# DSS_DSS_VP1_3020A000h register map
Vendor: Texas Instruments
Peripheral module from a debugger description file (folder am62L).
Registers are 32-bit, read-write, reset 0x0 unless marked. A register's access mark holds for its fields unless they carry their own. Offsets are as the file gives them; lines under a group give offsets from that group; [hi:lo] are bit positions; {n}, {i} and the like mark numbered series; 'fields as' and 'values as' point back to an identical list; <NAME> marks a mode.

## DSS_VP1
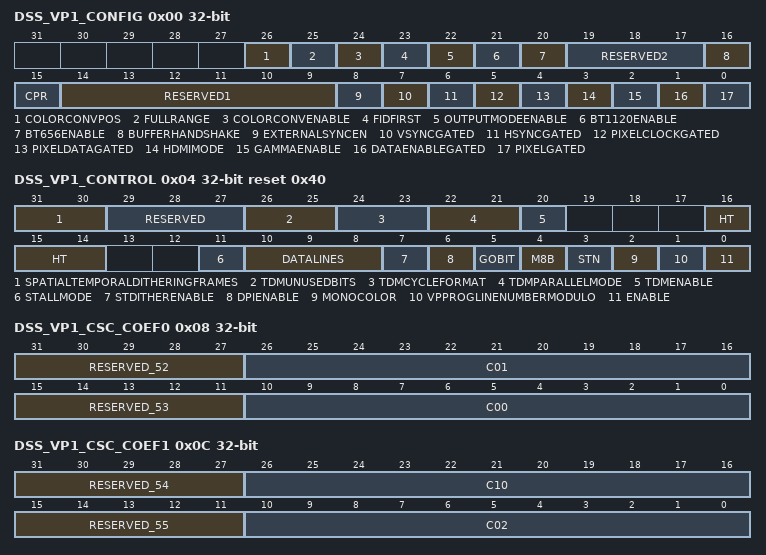
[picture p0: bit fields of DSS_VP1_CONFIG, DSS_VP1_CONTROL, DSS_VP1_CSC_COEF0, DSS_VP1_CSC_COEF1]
0x00 DSS_VP1_CONFIG access per field — The control register configures the Display Controller module for the VP output. Shadow register.
  [26] COLORCONVPOS rw — Determines the position of the COLORCONV module 0 CSC block is after GAMMA correction1 CSC block is before GAMMA correction
  [25] FULLRANGE rw — Color Space Conversion full range setting 0 Limited range selected.1 Full range selected.
  [24] COLORCONVENABLE rw — Enable the color space conversion. The coefficients and offsets used are all programmable and controlled by CPR_COEFF_* and CPR_OFFSET_* registers 0 Disable Color Space Conversion RGB to YUV1 Enable Color Space Conversion RGB to YUV
  [23] FIDFIRST rw — Selects the first field to output in case of interlace mode. In case of progressive mode, the value is not used 0 First field is even.1 Odd field is first.
  [22] OUTPUTMODEENABLE rw — Selects between progressive and interlace mode for the VP output 0 Progressive mode selected.1 Interlace mode selected.
  [21] BT1120ENABLE rw — Selects BT-1120 format on the VP output. It is not possible to enable BT656 and BT1120 at the same time one the same LCD output 0 BT-1120 is disabled.1 BT-1120 is enabled.
  [20] BT656ENABLE rw — Selects BT-656 format on the VP output. It is not possible to enable BT656 and BT1120 at the same time one the same LCD output 0 BT-656 is disabled.1 BT-656 is enabled.
  [19:17] RESERVED2 ro — Write 0's for future compatibility Reads return 0
  [16] BUFFERHANDSHAKE rw — Deprecated. Always write 0
  [15] CPR rw — Deprecated. Always write 0
  [14:9] RESERVED1 ro — Write 0's for future compatibility Reads return 0
  [8] EXTERNALSYNCEN rw — Deprecated. Always write 0
  [7] VSYNCGATED rw — VSYNC Gated Enabled [VP output]. Shadow bit-field 0 VSYNC Gated Disabled1 VSYNC Gated Enabled
  [6] HSYNCGATED rw — HSYNC Gated Enabled [VP output]. Shadow bit-field 0 HSYNC Gated Disabled1 HSYNC Gated Enabled
  [5] PIXELCLOCKGATED rw — Pixel Clock Gated Enabled [VP output]. Shadow bit-field 0 Pixel Clock Gated Disabled1 Pixel Clock Gated Enabled
  [4] PIXELDATAGATED rw — Pixel Data Gated Enabled [VP output]. Shadow bit-field 0 Pixel Data Gated Disabled1 Pixel Data Gated Enabled
  [3] HDMIMODE rw — Deprecated. Always write 0
  [2] GAMMAENABLE rw — Enable the gamma Shadow bit-field 0 Gamma disabled1 Gamma enabled
  [1] DATAENABLEGATED rw — DE Gated Enable Shadow bit-field 0 DE signal is not gated1 DE signal is gated.
  [0] PIXELGATED rw — Pixel Gated Enable. Shadow bit-field 0 Pixel clock always toggles - only in TFT mode1 Pixel clock only toggles when there is valid data to display -only in TFT mode
0x04 DSS_VP1_CONTROL access per field reset 0x40 — The control register configures the Display Controller module for the VP output
  [31:30] SPATIALTEMPORALDITHERINGFRAMES rw — Spatial/Temporal dithering number of frames for the VP output Shadow bit-field 0 Spatial only1 Spatial and temporal over 2 frames2 Spatial and temporal over 4 frames3 Reserved
  [29:27] RESERVED ro — Write 0's for future compatibility Reads return 0
  [26:25] TDMUNUSEDBITS rw — State of unused bits [TDM mode only] for the VP output Shadow bit-field 0 low level1 high level2 unchanged from previous state3 reserved
  [24:23] TDMCYCLEFORMAT rw — Cycle format [TDM mode only] for the VP output Shadow bit-field 0 1 cycle for 1 pixel1 2 cycles for 1 pixel2 3 cycles for 1 pixel3 3 cycles for 2 pixels
  [22:21] TDMPARALLELMODE rw — Output Interface width [TDM mode only] for the VP output Shadow bit-field 0 8-bit parallel output interface selected1 9-bit parallel output interface selected2 12-bit parallel output interface selected3 16-bit parallel output interface selected
  [20] TDMENABLE rw — Enable the multiple cycle format for the VP output Shadow bit-field 0 TDM disabled1 TDM enabled
  [16:14] HT rw — Hold Time for output. Shadow bit-field. Encoded value [from 1 to 8] to specify the number of external digital clock periods to hold the data [programmed value = value minus one]
  [11] STALLMODE rw — Deprecated. Always write 0
  [10:8] DATALINES rw — Width of the data bus on VP output Shadow bit-field 0 12-bit output aligned on the LSB of the pixel data interface1 16-bit output aligned on the LSB of the pixel data interface2 18-bit output aligned on the LSB of the pixel data interface3 24-bit output aligned on the LSB of the pixel data interface4 30-bit output aligned on the LSB of the pixel data interface5 36-bit output aligned on the LSB of the pixel data interface
  [7] STDITHERENABLE rw — Spatial Temporal dithering enable for the VP output Shadow bit-field 0 Spatial/Temporal dithering logic disabled1 Spatial/Temporal dithering logic enabled
  [6] DPIENABLE rw — Enable the DPI output and mdata[8] is driven by this bitfield, there is no other functionality in DSS_Nano driven by this bit . wr:immediate 0 DPI output disabled1 DPI output enabled
  [5] GOBIT rw — GO Command for the VP output. It is used to synchronize the pipelines associated with the VP output wr:immediate 0 The hardware has finished the synchronization1 Software has requested for synchronization after register updates and the hardware has not finished the synchronization
  [4] M8B rw — Deprecated. Always write 0
  [3] STN rw — Deprecated. Always write 0
  [2] MONOCOLOR rw — Deprecated. Always write 0
  [1] VPPROGLINENUMBERMODULO rw — Enable the modulo of the line number interrupt generation 0 Disable modulo1 Enable Modulo
  [0] ENABLE rw — Enable the video port output. wr:immediate 0 LCD output disabled-at the end of the frame when the bit is reset1 LCD output enabled
0x08 DSS_VP1_CSC_COEF0 access per field — The register configures the color space conversion matrix coefficients. Shadow register
  [31:27] RESERVED_52 ro — Write 0's for future compatibility. Reads return 0
  [26:16] C01 rw — C01 Coefficient. Encoded signed value [from -1024 to 1023]
  [15:11] RESERVED_53 ro — Write 0's for future compatibility. Reads return 0
  [10:0] C00 rw — C00 Coefficient. Encoded signed value [from -1024 to 1023]
0x0C DSS_VP1_CSC_COEF1 access per field — The register configures the color space conversion matrix coefficients. Shadow register
  [31:27] RESERVED_54 ro — Write 0's for future compatibility. Reads return 0
  [26:16] C10 rw — C10 Coefficient. Encoded signed value [from -1024 to 1023]
  [15:11] RESERVED_55 ro — Write 0's for future compatibility. Reads return 0
  [10:0] C02 rw — C02 Coefficient. Encoded signed value [from -1024 to 1023]
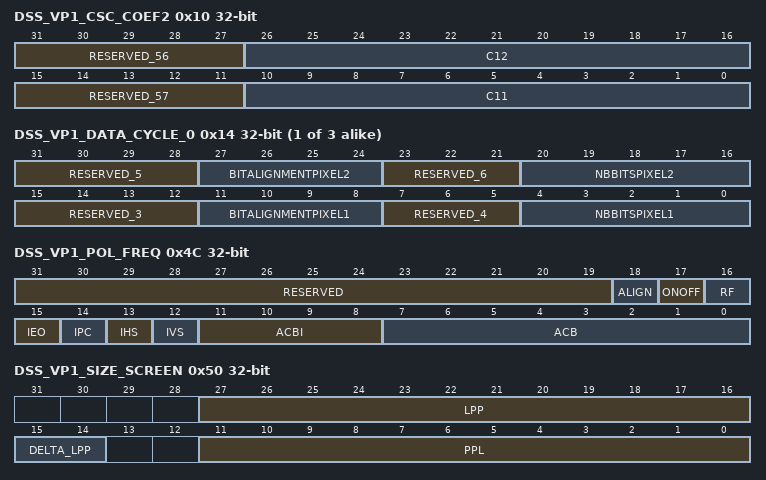
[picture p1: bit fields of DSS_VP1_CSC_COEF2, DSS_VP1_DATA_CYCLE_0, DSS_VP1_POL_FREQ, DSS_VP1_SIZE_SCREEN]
0x10 DSS_VP1_CSC_COEF2 access per field — The register configures the color space conversion matrix coefficients. Shadow register
  [31:27] RESERVED_56 ro — Write 0's for future compatibility Reads return 0
  [26:16] C12 rw — C12 Coefficient. Encoded signed value [from -1024 to 1023]
  [15:11] RESERVED_57 ro — Write 0's for future compatibility Reads return 0
  [10:0] C11 rw — C11 Coefficient. Encoded signed value [from -1024 to 1023]
{0x14+4i} DSS_VP1_DATA_CYCLE_{i} access per field (i=0..2) — The control register configures the output data format over up to 3 cycles. Shadow register
  [31:28] RESERVED_5 ro — Write 0's for future compatibility Reads return 0
  [27:24] BITALIGNMENTPIXEL2 rw — Bit alignment Alignment of the bits from pixel 2 on the output interface
  [23:21] RESERVED_6 ro — Write 0's for future compatibility Reads return 0
  [20:16] NBBITSPIXEL2 rw — Number of bits Number of bits from the pixel 2 [value from 0 to 16 bits]. The values from 17 to 31 are invalid
  [15:12] RESERVED_3 ro — Write 0's for future compatibility. Reads return 0
  [11:8] BITALIGNMENTPIXEL1 rw — Bit alignment Alignment of the bits from pixel 1 on the output interface
  [7:5] RESERVED_4 ro — Write 0's for future compatibility Reads return 0
  [4:0] NBBITSPIXEL1 rw — Number of bits Number of bits from the pixel 1 [value from 0 to 16 bits]. The values from 17 to 31 are invalid
0x44 DSS_VP1_LINE_NUMBER — The control register indicates the panel display line number for the interrupt and the DMA request. Shadow register
  [11:0] LINENUMBER — LCD panel line number programming LCD line number defines the line on which the programmable interrupt is generated and the DMA request occurs
0x4C DSS_VP1_POL_FREQ access per field — The register configures the signal configuration. Shadow register
  [31:19] RESERVED ro — Write 0's for future compatibility Reads return 0
  [18] ALIGN rw — Defines the alignment between HSYNC and VSYNC assertion 0 VSYNC and HSYNC are not aligned1 VSYNC and HSYNC assertions are aligned.
  [17] ONOFF rw — HSYNC/VSYNC Pixel clock Control On/Off 0 HSYNC and VSYNC are driven on opposite edges of pixel clock than pixel data1 HSYNC and VSYNC are driven according to bit 16
  [16] RF rw — Program HSYNC/VSYNC Rise or FallTo set HSYNC/VSYNC to pixel clock relationship, CTRL_MMR_DPI0_CLK_CTRL[9] DPI0_CLK_CTRL_SYNC_CLK_INVDIS setting should be opposite the [16] RF setting. 0 HSYNC and VSYNC are driven on falling edge of pixel clock -if bit 17 set to 11 HSYNC and VSYNC are driven on rising edge of pixel clock -if bit 17 set to 1
  [15] IEO rw — Invert output enable 0 DE is active high1 DE is active low
  [14] IPC rw — Invert pixel clockTo set data to pixel clock relationship, CTRL_MMR_DPI0_CLK_CTRL[8] DPI0_CLK_CTRL_DATA_CLK_INVDIS setting should be opposite the [14] IPC setting. 0 Data is driven on the LCD data lines on the rising-edge of the pixel clock1 Data is driven on the LCD data lines on the falling-edge of the pixel clock
  [13] IHS rw — Invert HSYNC 0 Hsync pin is active high and inactive low1 Hsync pin is active low and inactive high
  [12] IVS rw — Invert VSYNC 0 Vsync pin is active high and inactive low1 Vsync pin is active low and inactive high
  [11:8] ACBI rw — AC Bias Pin transitions per interrupt Value [from 0 to 15] used to specify the number of AC Bias pin transitions
  [7:0] ACB rw — AC Bias Pin Frequency Value [from 0 to 255] used to specify the number of line clocks to count before transitioning the AC Bias pin. This pin is used to periodically invert the polarity of the power supply to prevent DC charge build-up within the display
0x50 DSS_VP1_SIZE_SCREEN — The register configures the panel size horizontal and vertical. Shadow register. A delta value is used to indicate if the odd field has same vertical size as the even field or +/- one line.
  [27:16] LPP — Lines per panel Encoded value [from 1 to 4096] to specify the number of lines per panel [program to value minus one]
  [15:14] DELTA_LPP — Indicates the delta size value of the odd field compared to the even field 0 Same size1 Odd size is even size plus 12 Odd size is even size minus 1
  [11:0] PPL — Pixels per line Encoded value [from 1 to 4096] to specify the number of pixels contains within each line on the display [program to value minus one]. In STALL mode, any value is valid In non-STALL mode, only values multiple of 8 pixels are valid
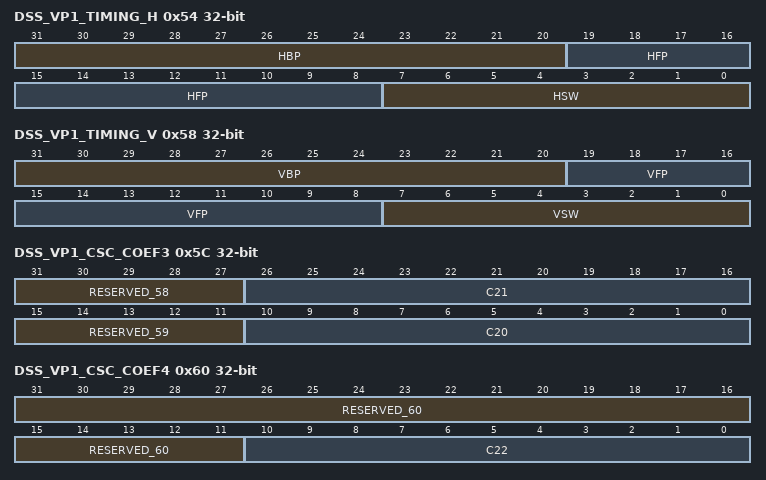
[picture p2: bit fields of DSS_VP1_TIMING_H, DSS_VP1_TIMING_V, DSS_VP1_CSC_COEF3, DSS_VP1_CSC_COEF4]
0x54 DSS_VP1_TIMING_H — The register configures the timing logic for the HSYNC signal. Shadow register
  [31:20] HBP — Horizontal Back Porch Encoded value [from 1 to 4096] to specify the number of pixel clock periods to add to the beginning of a line transmission before the first set of pixels is output to the display [program to value minus one] When in BT mode and interlaced, this field corresponds to the vertical field blanking No 2 for Even Field
  [19:8] HFP — Horizontal front porch Encoded value [from 1 to 4096] to specify the number of pixel clock periods to add to the end of a line transmission before line clock is asserted display [program to value minus one] When in BT mode and interlaced, this field corresponds to the vertical field blanking No 1 for Even Field
  [7:0] HSW — Horizontal synchronization pulse width Encoded value [from 1 to 256] to specify the number of pixel clock periods to pulse the line clock at the end of each line display [program to value minus one] When in BT mode, this field corresponds to the LSB 8-bits of the 12-bit horizontal blanking[BT_HBLANK[11:0]= {VSW[3:0],HSW[7:0]}]
0x58 DSS_VP1_TIMING_V — The register configures the timing logic for the VSYNC signal. Shadow register
  [31:20] VBP — Vertical back porch Encoded value [from 0 to 4095] to specify the number of line clock periods to add to the beginning of a frame When in BT mode and interlaced, this field corresponds to the vertical field blanking No 2 for Odd Field When in BT and in progressive mode, this field corresponds to the Vertical frame blanking No 2 before the first set of pixels is output to the display
  [19:8] VFP — Vertical front porch Encoded value [from 0 to 4095] to specify the number of line clock periods to add to the end of each frame When in BT mode and interlaced, this field corresponds to the vertical field blanking No 1 for Odd Field When in BT and in progressive mode, this field corresponds to the Vertical frame blanking No 2
  [7:0] VSW — Vertical synchronization pulse width Encoded value [from 1 to 256] to specify the number of line clock periods to pulse the frame clock [VSYNC] pin at the end of each frame after the end of frame wait [VFP] period elapses Frame clock uses as VSYNC signal in active mode When in BT mode, the lsb 4-bits of this field [VSW[3:0]] corresponds to the MSB 4-bits of the 12-bit horizontal blanking[BT_HBLANK= {VSW[3:0],HSW[7:0]}]
0x5C DSS_VP1_CSC_COEF3 access per field — The register configures the color space conversion matrix coefficients. Shadow register
  [31:27] RESERVED_58 ro — Write 0's for future compatibility. Reads return 0
  [26:16] C21 rw — C21 coefficient. Encoded signed value [from -1024 to 1023]
  [15:11] RESERVED_59 ro — Write 0's for future compatibility. Reads return 0
  [10:0] C20 rw — C20 coefficient. Encoded signed value [from -1024 to 1023]
0x60 DSS_VP1_CSC_COEF4 access per field — The register configures the color space conversion matrix coefficients. Shadow register
  [31:11] RESERVED_60 ro — Write 0's for future compatibility. Reads return 0
  [10:0] C22 rw — C22 Coefficient. Encoded signed value [from -1024 to 1023]
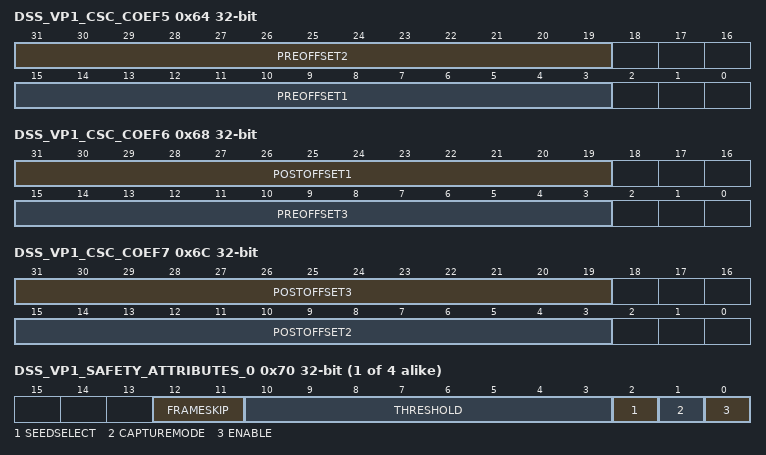
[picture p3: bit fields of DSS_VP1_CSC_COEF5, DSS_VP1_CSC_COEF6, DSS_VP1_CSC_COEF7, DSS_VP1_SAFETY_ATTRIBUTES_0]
0x64 DSS_VP1_CSC_COEF5 — The register configures the color space conversion matrix coefficients. Shadow register
  [31:19] PREOFFSET2 — Row-2 pre-offset. Encoded signed value [from -4096 to 4095]
  [15:3] PREOFFSET1 — Row1 pre-offset. Encoded signed value [from -4096 to 4095]
0x68 DSS_VP1_CSC_COEF6 — The register configures the color space conversion matrix coefficients. Shadow register
  [31:19] POSTOFFSET1 — Row-1 post-offset. Encoded signed value [from -4096 to 4095]
  [15:3] PREOFFSET3 — Row-3 pre-offset. Encoded signed value [from -4096 to 4095]
0x6C DSS_VP1_CSC_COEF7 — The register configures the color space conversion matrix coefficients. Shadow register
  [31:19] POSTOFFSET3 — Row-3 post-offset. Encoded signed value [from -4096 to 4095]
  [15:3] POSTOFFSET2 — Row-2 post-offset. Encoded signed value [from -4096 to 4095]
{0x70+4i} DSS_VP1_SAFETY_ATTRIBUTES_{i} (i=0..3) — The register configures the safety sub-region n. Shadow register
  [12:11] FRAMESKIP — Indicates which frames to be skipped while doing FRAMEFREEZE or DATACHECK [Useful for interlaced displays]. 0x0: No frames are skipped, 0x1: Even Frames are skipped starting from second frame after ENABLE, 0x2: Odd Frames are skipped starting from first frame after ENABLE, 0x3: Reserved 0 No frames are skipped1 Even Frames are skipped starting from second frame after ENABLE2 Odd Frames are skipped starting from first frame after ENABLE3 Reserved
  [10:3] THRESHOLD — Allowed maximum number of frames with the same frame signature When the freeze frame counter reaches 1 over this value [freeze_frame_thold+1], a freeze frame detection will occur Note: The freeze frame counter is cleared on reset -OR- MISR not enabled -OR- terminal count reached -OR- compare == no match
  [2] SEEDSELECT — Initial seed selection control 0 Initial seed is always 0xFFFF_FFFF1 Initial seed is defined by SAFETY_LFSR_START.SEED
  [1] CAPTUREMODE — Mode of operation of the safety check module 0 Frame freeze detect enabled1 Data correctness check enabled
  [0] ENABLE — Safety check Enable for the region Note: Transition from 0 to 1 clears the signature register
{0x90+4i} DSS_VP1_SAFETY_CAPT_SIGNATURE_{i} ro (i=0..3) — The register captures the signature from the MISR of the safety sub-region n. Shadow register
  [31:0] SIGNATURE — The register configures the reference signature of the safety sub-region n Shadow register
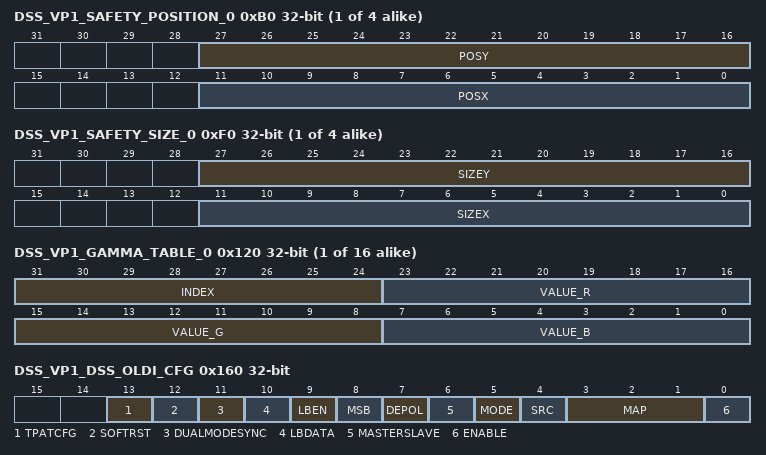
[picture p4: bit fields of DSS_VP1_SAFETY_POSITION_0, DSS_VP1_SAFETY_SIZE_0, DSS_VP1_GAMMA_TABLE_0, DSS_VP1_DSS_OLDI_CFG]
{0xB0+4i} DSS_VP1_SAFETY_POSITION_{i} (i=0..3) — The register configures the position of the safety sub-region n. Shadow register
  [27:16] POSY — Y position of the safety sub-region n. Encoded value [from 0 to 4095] to specify the Y position of the sub-region on the screen The first line on the top of the screen has the Y-position 0
  [11:0] POSX — X position of the safety sub-region n. Encoded value [from 0 to 4095] to specify the X position of the sub-region on the screen The first pixel on the left of the screen has the X-position 0
{0xD0+4i} DSS_VP1_SAFETY_REF_SIGNATURE_{i} (i=0..3) — The register configures the reference signature of the safety sub-region n. Shadow register
  [31:0] SIGNATURE
{0xF0+4i} DSS_VP1_SAFETY_SIZE_{i} (i=0..3) — The register configures the size of the safety sub-region n Shadow register.
  [27:16] SIZEY — Height of the safety sub-region n Encoded value [from 0 to 4095] to specify the height of the sub-region on the screen One line height region has value of 0
  [11:0] SIZEX — Width of the safety sub-region n Encoded value [from 0 to 4095] to specify the width of the sub-region on the screen One pixel wide region has value of 0
0x110 DSS_VP1_SAFETY_LFSR_SEED — The register configures the seed initial signature value of MISRs that are to be initialized with a user programmed initial value. Otherwise, the MISR is initialized with 0xFFFF_FFFF. Shadow register.
  [31:0] SEED — The register configures the seed [initial signature value] of MISRs that are to be initialized with a user programmed initial value Otherwise, the MISR is initialized with 0xFFFF_FFFF Shadow register
{0x120+4i} DSS_VP1_GAMMA_TABLE_{i} wo (i=0..15) — The register configures the gamma table on VP output.
  [31:24] INDEX — Defines the location in the table where the bit-fields VALUE_{R,G,B} is stored
  [23:16] VALUE_R — 8-bit R value to be stored in the gamma table
  [15:8] VALUE_G — 8-bit G value to be stored in the gamma table
  [7:0] VALUE_B — 8-bit B value to be stored in the gamma table
0x160 DSS_VP1_DSS_OLDI_CFG — This register configures the OLDI[N:0] modules connected to the DSS
  [13] TPATCFG — Test pattern Config
  [12] SOFTRST — SoftWare Reset. By default, OLDI is kept under reset 0 Software Reset is asserted -OLDI is under reset1 Software Reset is deasserted
  [11] DUALMODESYNC — DualMode Sync 0 Dual Mode operation is disabled1 Dual Mode Operation is enabled
  [10] LBDATA — LoopBack Data
  [9] LBEN — LoopBack Enable 0 disabled1 enabled
  [8] MSB — DSS bit-depth [for 18b LVDS only] 0 Input from DSS is 18b. Use RGB data[17:0] as 18b RGB1 Input from DSS is 24b. Use 6 msbs each of RGB data R[7:2], G[7:2] and B[7:2].
  [7] DEPOL — Polarity of the DE signal 0 DE is active-high1 DE is active-low
  [6] MASTERSLAVE — Master selection in Dual mode only [typically tied off in the SoC] 0 Master in Dual mode operation1 Slave in Dual mode operation
  [5] MODE — Single mode or duplicate mode 0 Single mode selected -independent operation1 Duplicate mode selected -synchronized operation
  [4] SRC — Source Channel 0 Video-0 is the source1 Video-1 is the source
  [3:1] MAP — Configuration of OLDI mapping Also indicates dual mode 0 Single-link 18-bit1 Single-link 24-bit JEIDA2 Single-link 24-bit4 Dual-link 18-bit5 Dual-link 24-bit JEIDA6 Dual-link 24-bit
  [0] ENABLE — OLDI Enable 0 ENABLED1 ENABLED
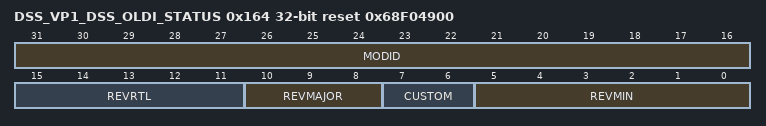
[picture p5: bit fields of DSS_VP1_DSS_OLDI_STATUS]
0x164 DSS_VP1_DSS_OLDI_STATUS ro reset 0x68F04900 — This register captures the PID from the OLDI[N:0] modules connected to the DSS. Reads 0x0 if no OLDI is connected
  [31:16] MODID — Module ID Field
  [15:11] REVRTL — RTL Revision
  [10:8] REVMAJOR — Major Revision
  [7:6] CUSTOM
  [5:0] REVMIN — Minor Revision
0x168 DSS_VP1_DSS_OLDI_LB ro — This register captures the Loopback data from OLDI
  [9:0] LBRDATA — Returned Data from Loopback
